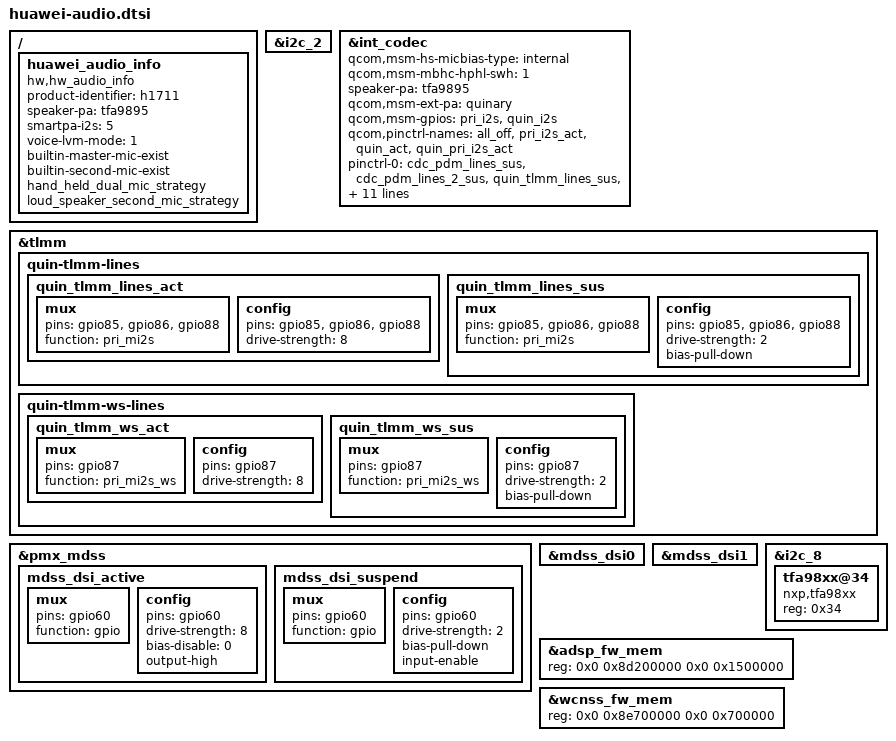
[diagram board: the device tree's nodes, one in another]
/ {
    huawei_audio_info {
        compatible = "hw,hw_audio_info";
        product-identifier = "h1711";
        speaker-pa = "tfa9895";
        smartpa-i2s = <5>;
        /*disable lvm: set voice-lvm-mode 1*/
        voice-lvm-mode = "1";
        builtin-master-mic-exist;
        builtin-second-mic-exist;
        hand_held_dual_mic_strategy;
        status = "ok";
        loud_speaker_second_mic_strategy;
    };
};

&i2c_2 {
	/delete-node/ wsa881x-i2c-codec@e;
	/delete-node/ wsa881x-i2c-codec@44;
	/delete-node/ wsa881x-i2c-codec@f;
	/delete-node/ wsa881x-i2c-codec@45;
};

&int_codec {
	/delete-property/ qcom,cdc-us-euro-gpios;
	qcom,msm-hs-micbias-type = "internal";
	qcom,msm-mbhc-hphl-swh = <1>;
	speaker-pa = "tfa9895";
	qcom,msm-ext-pa = "quinary";
	qcom,msm-gpios =
		"pri_i2s",
		"quin_i2s";
	qcom,pinctrl-names =
		"all_off",
		"pri_i2s_act",
		"quin_act",
		"quin_pri_i2s_act";
	pinctrl-names =
		"all_off",
		"pri_i2s_act",
		"quin_act",
		"quin_pri_i2s_act";
	pinctrl-0 = <&cdc_pdm_lines_sus
			&cdc_pdm_lines_2_sus
			&quin_tlmm_lines_sus &quin_tlmm_ws_sus>;
	pinctrl-1 = <&cdc_pdm_lines_act
			&cdc_pdm_lines_2_act
			&quin_tlmm_lines_sus &quin_tlmm_ws_sus>;
	pinctrl-2 = <&cdc_pdm_lines_sus
			&cdc_pdm_lines_2_sus
			&quin_tlmm_lines_act &quin_tlmm_ws_act>;
	pinctrl-3 = <&cdc_pdm_lines_act
			&cdc_pdm_lines_2_act
			&quin_tlmm_lines_act &quin_tlmm_ws_act>;
	/delete-property/ pinctrl-4 ;
	/delete-property/ pinctrl-5 ;
	/delete-property/ pinctrl-6;
	/delete-property/ pinctrl-7;
	huawei,hac_gpio = <&tlmm 129 0>; /*GPIO For HAC*/
};

&tlmm {
	quin-tlmm-lines {
		quin_tlmm_lines_act: quin_tlmm_lines_act {
			mux {
				pins = "gpio85", "gpio86", "gpio88";
				function = "pri_mi2s";
			};

			config {
				pins = "gpio85", "gpio86", "gpio88";
				drive-strength = <8>;
			};
		};

		quin_tlmm_lines_sus: quin_tlmm_lines_sus {
			mux {
				pins = "gpio85", "gpio86", "gpio88";
				function = "pri_mi2s";
			};

			config {
				pins = "gpio85", "gpio86", "gpio88";
				drive-strength = <2>;
				bias-pull-down;
			};
		};
	};

	quin-tlmm-ws-lines {
		quin_tlmm_ws_act: quin_tlmm_ws_act {
			mux {
				pins = "gpio87";
				function = "pri_mi2s_ws";
			};

			config {
				pins = "gpio87";
				drive-strength = <8>;
			};
		};

		quin_tlmm_ws_sus: quin_tlmm_ws_sus {
			mux {
				pins = "gpio87";
				function = "pri_mi2s_ws";
			};

			config {
				pins = "gpio87";
				drive-strength = <2>;
				bias-pull-down;
			};
		};
	};
};


&pmx_mdss {
	mdss_dsi_active: mdss_dsi_active {
		mux {
			pins = "gpio60";
			function = "gpio";
		};

		config {
			pins = "gpio60";
			drive-strength = <8>; /* 8 mA */
			bias-disable = <0>; /* no pull */
			output-high;
		};
	};
	mdss_dsi_suspend: mdss_dsi_suspend {
		mux {
			pins = "gpio60";
			function = "gpio";
		};

		config {
			pins = "gpio60";
			drive-strength = <2>; /* 2 mA */
			bias-pull-down; /* pull down */
			input-enable;
		};
	};
};

&mdss_dsi0 {
	/delete-property/ qcom,platform-enable-gpio;
	/delete-property/ qcom,platform-bklight-en-gpio;
};

&mdss_dsi1 {
	/delete-property/ qcom,platform-enable-gpio;
	/delete-property/ qcom,platform-bklight-en-gpio;
};

&i2c_8 {
	status = "ok";
	tfa98xx@34 {
		compatible = "nxp,tfa98xx";
		reg = <0x34>;
	};
};

&adsp_fw_mem {
	reg = <0x0 0x8d200000 0x0 0x1500000>;
};

&wcnss_fw_mem {
	reg = <0x0 0x8e700000 0x0 0x700000>;
};
